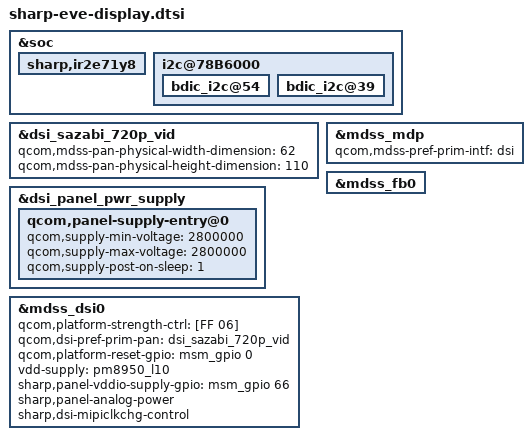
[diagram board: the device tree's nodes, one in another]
/* Copyright (c) 2016, The Linux Foundation. All rights reserved.
 *
 * This program is free software; you can redistribute it and/or modify
 * it under the terms of the GNU General Public License version 2 and
 * only version 2 as published by the Free Software Foundation.
 *
 * This program is distributed in the hope that it will be useful,
 * but WITHOUT ANY WARRANTY; without even the implied warranty of
 * MERCHANTABILITY or FITNESS FOR A PARTICULAR PURPOSE.  See the
 * GNU General Public License for more details.
 */

#include "sharp-ir2e71y.dtsi"
#include "dsi-panel-sazabi-720p-video.dtsi"

&soc {
	sharp,ir2e71y8 {
		status = "ok";
	};
};

&soc {
	i2c@78B6000 {
		bdic_i2c@54 {
			status = "ok";
		};

		bdic_i2c@39 {
			status = "ok";
		};
	};
};

&dsi_sazabi_720p_vid {
	status = "ok";

	qcom,mdss-pan-physical-width-dimension = <62>;
	qcom,mdss-pan-physical-height-dimension = <110>;
};

&mdss_mdp {
	qcom,mdss-pref-prim-intf = "dsi";
};

&dsi_panel_pwr_supply {
	qcom,panel-supply-entry@0 {
		qcom,supply-min-voltage = <2800000>;
		qcom,supply-max-voltage = <2800000>;
		qcom,supply-post-on-sleep = <1>;
	};
	/delete-node/ qcom,panel-supply-entry@1;
	/delete-node/ qcom,panel-supply-entry@2;
	/delete-node/ qcom,panel-supply-entry@3;
};

&mdss_dsi0 {
	qcom,platform-strength-ctrl = [FF 06];
	qcom,dsi-pref-prim-pan=<&dsi_sazabi_720p_vid>;
	qcom,platform-reset-gpio = <&msm_gpio 0 0>;

	vdd-supply = <&pm8950_l10>;
	/delete-property/ qcom,platform-enable-gpio;
	/delete-property/ vddio-supply;
	/delete-property/ lab-supply;
	/delete-property/ ibb-supply;

	/delete-property/ qcom,dsi-panel-bias-vreg;
	/delete-property/ qcom,platform-bklight-en-gpio;

	/delete-property/ pinctrl-names;
	/delete-property/ pinctrl-0;
	/delete-property/ pinctrl-1;

	sharp,panel-vddio-supply-gpio = <&msm_gpio 66 0>;
	sharp,panel-analog-power;

	sharp,dsi-mipiclkchg-control;
};

&mdss_fb0 {
	/delete-property/ qcom,mdss-fb-splash-logo-enabled;
};
